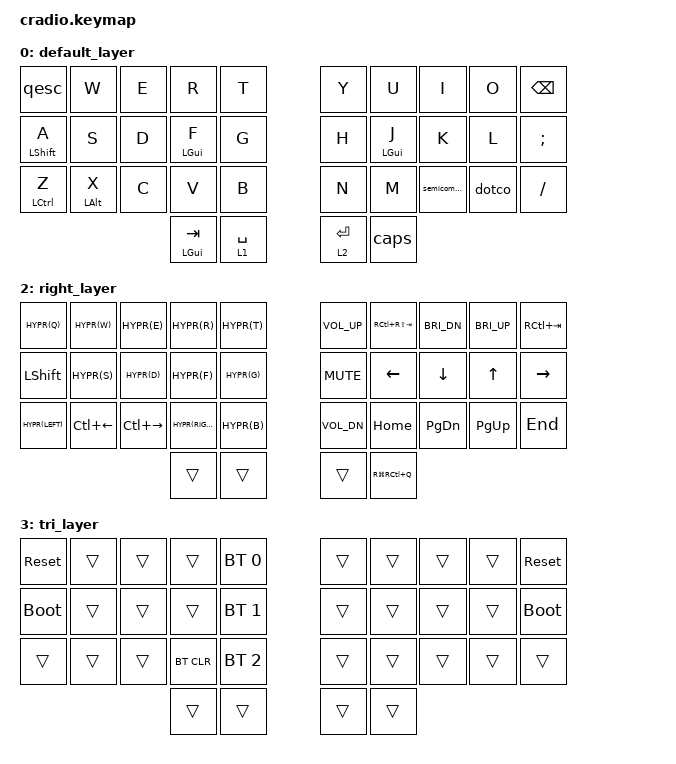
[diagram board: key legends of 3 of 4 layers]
// Copyright (c) 2022 The ZMK Contributors
// SPDX-License-Identifier: MIT

#include <behaviors.dtsi>
#include <dt-bindings/zmk/keys.h>
#include <dt-bindings/zmk/bt.h>

// Home row mods macro
// #define HYPR LC(LA(LG(LSHFT)))
#define HYPR(k1) &kp LC(LA(LG(LS(k1))))
/ {
    behaviors {
        ht: hold_tap {
            compatible = "zmk,behavior-hold-tap";
            #binding-cells = <2>;
            flavor = "tap-preferred";
            tapping-term-ms = <220>;
            quick-tap-ms = <150>;
            require-prior-idle-ms = <100>;
            bindings = <&kp>, <&kp>;
        };
        caps: capsword {
            compatible = "zmk,behavior-tap-dance";
            #binding-cells = <0>;
            tapping-term-ms = <200>;
            bindings = <&sk RSHFT>, <&caps_word>;
        };
        semicomma: comma_semi {
            compatible = "zmk,behavior-mod-morph";
            #binding-cells = <0>;
            bindings = <&kp COMMA>, <&kp P>;
            mods = <(MOD_LSFT|MOD_RSFT)>;
        };
        dotco: dot_colon {
            compatible = "zmk,behavior-mod-morph";
            #binding-cells = <0>;
            bindings = <&kp DOT>, <&kp LS(P)>;
            mods = <(MOD_LSFT|MOD_RSFT)>;
        };
        qesc: q_esc {
            compatible = "zmk,behavior-tap-dance";
            #binding-cells = <0>;
            tapping-term-ms = <200>;
            bindings = <&kp Q>, <&kp ESC>;
        };
    };


    conditional_layers {
        compatible = "zmk,conditional-layers";
        tri_layer {
            if-layers = <1 2>;
            then-layer = <3>;
        };
    };

    keymap {
        compatible = "zmk,keymap";
        default_layer {
            bindings = <
        //╭──────────┬──────────┬──────────┬──────────┬──────────╮   ╭──────────┬──────────┬──────────┬──────────┬──────────╮
        //│  Q       │  W       │  E       │  R       │  T       │   │  Y       │  U       │  I       │  O       │  P       │
           &qesc      &kp W      &kp E      &kp R      &kp T          &kp Y      &kp U      &kp I      &kp O      &kp BSPC
        //├──────────┼──────────┼──────────┼──────────┼──────────┤   ├──────────┼──────────┼──────────┼──────────┼──────────┤
        //│  A       │  S       │  D       │  F       │  G       │   │  H       │  J       │  K       │  L       │; "       │
          &ht LSHFT A &kp S      &kp D      &ht LGUI F &kp G          &kp H      &ht LGUI J &kp  K     &kp  L     &kp SEMI
        //├──────────┼──────────┼──────────┼──────────┼──────────┤   ├──────────┼──────────┼──────────┼──────────┼──────────┤
        //│  Z       │  X       │  C       │  V       │  B       │   │  N       │  M       │ , ;      │ . :      │ / ?      │
          &ht LCTRL Z &ht LALT X &kp C      &kp V      &kp B          &kp N      &kp M      &semicomma &dotco     &kp FSLH
        //╰──────────┴──────────┴──────────┼──────────┼──────────┤   ├──────────┼──────────┼──────────┴──────────┴──────────╯
                                          &ht LGUI TAB &lt 1 SPACE    &lt 2 ENTER &caps
        //                                 ╰──────────┴──────────╯   ╰──────────┴──────────╯
            >;
        };

        left_layer {
            bindings = <
        //╭──────────┬──────────┬──────────┬──────────┬──────────╮   ╭──────────┬──────────┬──────────┬──────────┬──────────╮
        //│ !        │  @       │  #       │  $       │  %       │   │ *        │ 7        │ 8        │ 9        │          │
           &kp EXCL   &kp AT     &kp HASH   &kp DLLR   &kp PRCNT      &kp ASTRK  &kp N7     &kp N8     &kp N9     &trans
        //├──────────┼──────────┼──────────┼──────────┼──────────┤   ├──────────┼──────────┼──────────┼──────────┼──────────┤
        //│  \       │  '       │  (       │  )       │  =       │   │ -        │ 4        │ 5        │ 6        │  0       │
           &kp BSLH   &kp SQT    &kp LPAR   &kp RPAR   &kp EQUAL      &kp MINUS  &kp N4     &kp N5     &kp N6     &kp N0
        //├──────────┼──────────┼──────────┼──────────┼──────────┤   ├──────────┼──────────┼──────────┼──────────┼──────────┤
        //│ <        │  >       │  [       │  ]       │   &      │   │ +        │ 1        │  2       │ 3        │  TILDE   │
           &kp LT     &kp GT     &kp LBKT   &kp RBKT   &kp AMPS       &kp PLUS   &kp N1     &kp N2     &kp N3     &kp TILDE
        //╰──────────┴──────────┴──────────┼──────────┼──────────┤   ├──────────┼──────────┼──────────┴──────────┴──────────╯
                                    &kp RG(RC(RS(N4))) &trans         &trans     &trans
        //                                 ╰──────────┴──────────╯   ╰──────────┴──────────╯
            >;
        };


        right_layer {
            bindings = <
        //╭──────────┬──────────┬──────────┬──────────┬──────────╮   ╭──────────┬──────────┬──────────┬──────────┬──────────╮
        //│          │          │          │          │          │   │          │          │          │          │          │
           HYPR(Q)    HYPR(W)    HYPR(E)    HYPR(R)    HYPR(T)       &kp C_VOL_UP &kp RC(RS(TAB)) &kp C_BRI_DN &kp C_BRI_UP &kp RC(TAB)
        //├──────────┼──────────┼──────────┼──────────┼──────────┤   ├──────────┼──────────┼──────────┼──────────┼──────────┤
        //│          │          │          │          │          │   │          │          │          │          │          │
           &kp LSHFT  HYPR(S)    HYPR(D)    HYPR(F)    HYPR(G)        &kp C_MUTE  &kp LEFT  &kp DOWN   &kp UP     &kp RIGHT
        //├──────────┼──────────┼──────────┼──────────┼──────────┤   ├──────────┼──────────┼──────────┼──────────┼──────────┤
        //│          │          │          │          │          │   │          │          │          │          │          │
         HYPR(LEFT) &kp LC(LEFT) &kp LC(RIGHT) HYPR(RIGHT) HYPR(B)    &kp C_VOL_DN &kp HOME &kp PG_DN  &kp PG_UP  &kp END
        //╰──────────┴──────────┴──────────┼──────────┼──────────┤   ├──────────┼──────────┼──────────┴──────────┴──────────╯
                                            &trans     &trans         &trans    &kp RG(RC(Q))
        //                                 ╰──────────┴──────────╯   ╰──────────┴──────────╯
            >;
        };
        
        tri_layer {
            bindings = <
        //╭──────────┬──────────┬──────────┬──────────┬──────────╮   ╭──────────┬──────────┬──────────┬──────────┬──────────╮
        //│ RESET    │          │          │          │PROFILE 0 │   │          │          │          │          │  RESET   │
           &sys_reset  &trans     &trans     &trans    &bt BT_SEL 0    &trans     &trans     &trans     &trans    &sys_reset
        //├──────────┼──────────┼──────────┼──────────┼──────────┤   ├──────────┼──────────┼──────────┼──────────┼──────────┤
        //│BOOTLOADER│          │          │          │PROFILE 1 │   │          │          │          │          │BOOTLOADER│
          &bootloader  &trans     &trans     &trans    &bt BT_SEL 1    &trans     &trans     &trans     &trans    &bootloader
        //├──────────┼──────────┼──────────┼──────────┼──────────┤   ├──────────┼──────────┼──────────┼──────────┼──────────┤
        //│          │          │          │ CLEAR BT │PROFILE 2 │   │          │          │          │          │          │
            &trans     &trans     &trans    &bt BT_CLR &bt BT_SEL 2    &trans     &trans     &trans     &trans     &trans
        //╰──────────┴──────────┴──────────┼──────────┼──────────┤   ├──────────┼──────────┼──────────┴──────────┴──────────╯
                                             &trans     &trans         &trans     &trans
        //                                 ╰──────────┴──────────╯   ╰──────────┴──────────╯
            >;
        };
    };
};
